AUTOSAR XML (schema 00049)
package /Client2App
  process design Client2Design: executable=client2d
package /Client2App/exe
  executable client2d: category=APPLICATION_LEVEL, logging-behavior=USES-LOGGING, reporting-behavior=REPORTS-EXECUTION-STATE
    root sw component prototype client2: application-type=client2
package /Client2App/swc
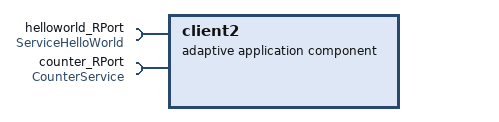
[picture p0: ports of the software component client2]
  adaptive application sw component type client2
    require port helloworld_RPort: required-interface=ServiceHelloWorld
    require port counter_RPort: required-interface=CounterService
